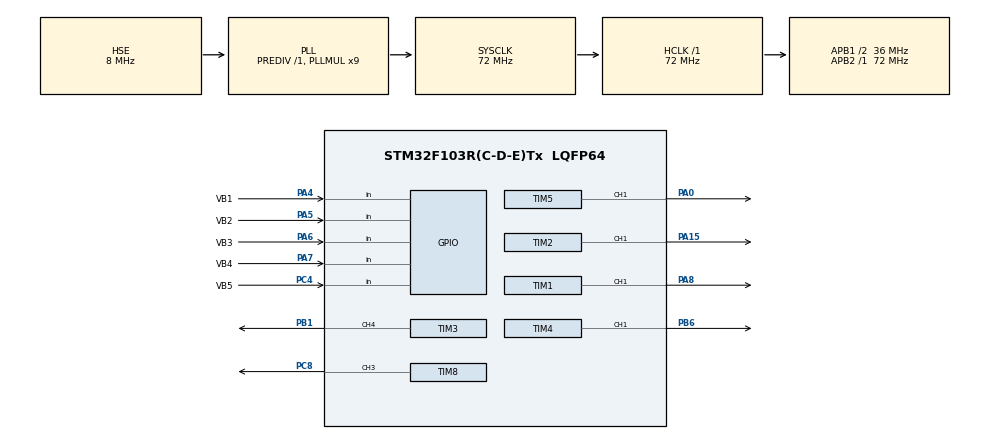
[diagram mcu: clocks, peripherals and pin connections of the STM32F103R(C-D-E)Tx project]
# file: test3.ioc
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Dma.Request0=TIM1_CH1
Dma.Request1=TIM2_CH1
Dma.Request2=TIM4_CH1
Dma.Request3=TIM3_CH4/UP
Dma.Request4=TIM5_CH1
Dma.Request5=TIM8_CH3/UP
Dma.TIM1_CH1.0.Direction=DMA_MEMORY_TO_PERIPH
Dma.TIM1_CH1.0.Instance=DMA1_Channel2
Dma.TIM1_CH1.0.MemDataAlignment=DMA_MDATAALIGN_WORD
Dma.TIM1_CH1.0.MemInc=DMA_MINC_ENABLE
Dma.TIM1_CH1.0.Mode=DMA_NORMAL
Dma.TIM1_CH1.0.PeriphDataAlignment=DMA_PDATAALIGN_WORD
Dma.TIM1_CH1.0.PeriphInc=DMA_PINC_DISABLE
Dma.TIM1_CH1.0.Priority=DMA_PRIORITY_LOW
Dma.TIM2_CH1.1.Direction=DMA_MEMORY_TO_PERIPH
Dma.TIM2_CH1.1.Instance=DMA1_Channel5
Dma.TIM2_CH1.1.MemDataAlignment=DMA_MDATAALIGN_WORD
Dma.TIM2_CH1.1.MemInc=DMA_MINC_ENABLE
Dma.TIM2_CH1.1.Mode=DMA_NORMAL
Dma.TIM2_CH1.1.PeriphDataAlignment=DMA_PDATAALIGN_WORD
Dma.TIM2_CH1.1.PeriphInc=DMA_PINC_DISABLE
Dma.TIM2_CH1.1.Priority=DMA_PRIORITY_LOW
Dma.TIM3_CH4/UP.3.Direction=DMA_MEMORY_TO_PERIPH
Dma.TIM3_CH4/UP.3.Instance=DMA1_Channel3
Dma.TIM3_CH4/UP.3.MemDataAlignment=DMA_MDATAALIGN_WORD
Dma.TIM3_CH4/UP.3.MemInc=DMA_MINC_ENABLE
Dma.TIM3_CH4/UP.3.Mode=DMA_NORMAL
Dma.TIM3_CH4/UP.3.PeriphDataAlignment=DMA_PDATAALIGN_WORD
Dma.TIM3_CH4/UP.3.PeriphInc=DMA_PINC_DISABLE
Dma.TIM3_CH4/UP.3.Priority=DMA_PRIORITY_LOW
Dma.TIM4_CH1.2.Direction=DMA_MEMORY_TO_PERIPH
Dma.TIM4_CH1.2.Instance=DMA1_Channel1
Dma.TIM4_CH1.2.MemDataAlignment=DMA_MDATAALIGN_WORD
Dma.TIM4_CH1.2.MemInc=DMA_MINC_ENABLE
Dma.TIM4_CH1.2.Mode=DMA_NORMAL
Dma.TIM4_CH1.2.PeriphDataAlignment=DMA_PDATAALIGN_WORD
Dma.TIM4_CH1.2.PeriphInc=DMA_PINC_DISABLE
Dma.TIM4_CH1.2.Priority=DMA_PRIORITY_LOW
Dma.TIM5_CH1.4.Direction=DMA_MEMORY_TO_PERIPH
Dma.TIM5_CH1.4.Instance=DMA2_Channel5
Dma.TIM5_CH1.4.MemDataAlignment=DMA_MDATAALIGN_WORD
Dma.TIM5_CH1.4.MemInc=DMA_MINC_ENABLE
Dma.TIM5_CH1.4.Mode=DMA_NORMAL
Dma.TIM5_CH1.4.PeriphDataAlignment=DMA_PDATAALIGN_WORD
Dma.TIM5_CH1.4.PeriphInc=DMA_PINC_DISABLE
Dma.TIM5_CH1.4.Priority=DMA_PRIORITY_LOW
Dma.TIM8_CH3/UP.5.Direction=DMA_MEMORY_TO_PERIPH
Dma.TIM8_CH3/UP.5.Instance=DMA2_Channel1
Dma.TIM8_CH3/UP.5.MemDataAlignment=DMA_MDATAALIGN_WORD
Dma.TIM8_CH3/UP.5.MemInc=DMA_MINC_ENABLE
Dma.TIM8_CH3/UP.5.Mode=DMA_NORMAL
Dma.TIM8_CH3/UP.5.PeriphDataAlignment=DMA_PDATAALIGN_WORD
Dma.TIM8_CH3/UP.5.PeriphInc=DMA_PINC_DISABLE
Dma.TIM8_CH3/UP.5.Priority=DMA_PRIORITY_LOW
Mcu.Family=STM32F1
Mcu.Name=STM32F103R(C-D-E)Tx
Mcu.Package=LQFP64
NVIC.DMA1_Channel1_IRQn=true\:5\:0\:true\:false\:true\:false\:true
NVIC.DMA1_Channel2_IRQn=true\:5\:0\:true\:false\:true\:false\:true
NVIC.DMA1_Channel3_IRQn=true\:5\:0\:true\:false\:true\:false\:true
NVIC.DMA1_Channel5_IRQn=true\:5\:0\:true\:false\:true\:false\:true
NVIC.DMA2_Channel1_IRQn=true\:5\:0\:true\:false\:true\:false\:true
NVIC.DMA2_Channel4_5_IRQn=true\:6\:0\:true\:false\:true\:false\:true
NVIC.PriorityGroup=NVIC_PRIORITYGROUP_4
PA0-WKUP.Signal=S_TIM5_CH1
PA13.Mode=Serial_Wire
PA13.Signal=SYS_JTMS-SWDIO
PA14.Mode=Serial_Wire
PA14.Signal=SYS_JTCK-SWCLK
PA15.Signal=S_TIM2_CH1_ETR
PA4.GPIO_Label=VB1
PA4.GPIO_PuPd=GPIO_PULLDOWN
PA4.Signal=GPIO_Input
PA5.GPIO_Label=VB2
PA5.GPIO_PuPd=GPIO_PULLDOWN
PA5.Signal=GPIO_Input
PA6.GPIO_Label=VB3
PA6.GPIO_PuPd=GPIO_PULLDOWN
PA6.Signal=GPIO_Input
PA7.GPIO_Label=VB4
PA7.GPIO_PuPd=GPIO_PULLDOWN
PA7.Signal=GPIO_Input
PA8.Signal=S_TIM1_CH1
PB1.Signal=S_TIM3_CH4
PB6.Signal=S_TIM4_CH1
PC4.GPIO_Label=VB5
PC4.GPIO_PuPd=GPIO_PULLDOWN
PC4.Signal=GPIO_Input
PC8.Signal=S_TIM8_CH3
PD0-OSC_IN.Mode=HSE-External-Oscillator
PD0-OSC_IN.Signal=RCC_OSC_IN
PD1-OSC_OUT.Mode=HSE-External-Oscillator
PD1-OSC_OUT.Signal=RCC_OSC_OUT
ProjectManager.HeapSize=0x400
ProjectManager.StackSize=0x500
ProjectManager.TargetToolchain=STM32CubeIDE
RCC.AHBFreq_Value=72000000
RCC.APB1CLKDivider=RCC_HCLK_DIV2
RCC.APB1Freq_Value=36000000
RCC.APB1TimFreq_Value=72000000
RCC.APB2Freq_Value=72000000
RCC.APB2TimFreq_Value=72000000
RCC.HCLKFreq_Value=72000000
RCC.PLLMUL=RCC_PLL_MUL9
RCC.PLLSourceVirtual=RCC_PLLSOURCE_HSE
RCC.SYSCLKFreq_VALUE=72000000
RCC.SYSCLKSource=RCC_SYSCLKSOURCE_PLLCLK
RCC.USBFreq_Value=72000000
SH.S_TIM1_CH1.0=TIM1_CH1,PWM Generation1 CH1
SH.S_TIM2_CH1_ETR.0=TIM2_CH1,PWM Generation1 CH1
SH.S_TIM3_CH4.0=TIM3_CH4,PWM Generation4 CH4
SH.S_TIM4_CH1.0=TIM4_CH1,PWM Generation1 CH1
SH.S_TIM5_CH1.0=TIM5_CH1,PWM Generation1 CH1
SH.S_TIM8_CH3.0=TIM8_CH3,PWM Generation3 CH3
TIM1.Channel-PWM\ Generation1\ CH1=TIM_CHANNEL_1
TIM1.Period=89
TIM2.Channel-PWM\ Generation1\ CH1=TIM_CHANNEL_1
TIM2.Period=89
TIM3.Channel-PWM\ Generation4\ CH4=TIM_CHANNEL_4
TIM3.Period=89
TIM4.Channel-PWM\ Generation1\ CH1=TIM_CHANNEL_1
TIM4.Period=89
TIM5.Channel-PWM\ Generation1\ CH1=TIM_CHANNEL_1
TIM5.Period=89
TIM8.Channel-PWM\ Generation3\ CH3=TIM_CHANNEL_3
TIM8.Period=89
VP_TIM1_VS_ClockSourceINT.Mode=Internal
VP_TIM2_VS_ClockSourceINT.Mode=Internal
VP_TIM3_VS_ClockSourceINT.Mode=Internal
VP_TIM4_VS_ClockSourceINT.Mode=Internal
VP_TIM5_VS_ClockSourceINT.Mode=Internal
VP_TIM8_VS_ClockSourceINT.Mode=Internal
board=custom

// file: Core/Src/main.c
/* USER CODE BEGIN Header */
/**
 ******************************************************************************
 * @file           : main.c
 * @brief          : Main program body
 ******************************************************************************
 * @attention
 *
 * Copyright (c) 2023 STMicroelectronics.
 * All rights reserved.
 *
 * This software is licensed under terms that can be found in the LICENSE file
 * in the root directory of this software component.
 * If no LICENSE file comes with this software, it is provided AS-IS.
 *
 ******************************************************************************
 */
/* USER CODE END Header */
#include "main.h"
#include "dma.h"
#include "tim.h"
#include "gpio.h"

/* USER CODE BEGIN Includes */
#include "WS2812.h"
#include "ctr.h"
// #include "Cmaster.h"
#include "vibra.h"
/* USER CODE END Includes */

void SystemClock_Config(void);

/* USER CODE BEGIN 0 */
int Step;
/* USER CODE END 0 */

int main(void)
{

  /* MCU Configuration--------------------------------------------------------*/

  /* Reset of all peripherals, Initializes the Flash interface and the Systick. */
  HAL_Init();

  /* Configure the system clock */
  SystemClock_Config();

  /* USER CODE BEGIN SysInit */
  int Step=0;
  /* USER CODE END SysInit */

  /* Initialize all configured peripherals */
  MX_GPIO_Init();
  MX_DMA_Init();
  MX_TIM1_Init();
  MX_TIM2_Init();
  MX_TIM3_Init();
  MX_TIM4_Init();
  MX_TIM5_Init();
  MX_TIM8_Init();
  /* USER CODE BEGIN 2 */
  //	ALL_UpdateBuf();
  boot_init();
  // Rand_num();
  // PC8
  /* USER CODE END 2 */

  /* Infinite loop */
  while (1) {

    /* USER CODE BEGIN 3 */
    // ʹ����
    // LED_YUAN_Init();
    //  Vibra_monitor();
    //  Trigger_Switchstate();
    //  Vibra_monitor();

    //  fan_logic();
    //  ctr_fan(Step,0x00005F);
    // Test(1,0x00005F);
    //		ALL_ClearBuf();
    //		ALL_UpdateBuf();

    //		Target_Init();

    //		ALL_ClearBuf();
    //		ALL_UpdateBuf();

    //////

    // ������
    //		Vibra_monitor();
    //		Ctr_Fan(Step,0x000010);
    //		ALL_ClearBuf();
    //		ALL_UpdateBuf();
    ///////

    //		Step = Step+2;
    //		if(Step == 34){
    //			Step = 0;
    //		}
  }
  /* USER CODE END 3 */
}

void SystemClock_Config(void)
{
  RCC_OscInitTypeDef RCC_OscInitStruct = {0};
  RCC_ClkInitTypeDef RCC_ClkInitStruct = {0};

  /** Initializes the RCC Oscillators according to the specified parameters
  * in the RCC_OscInitTypeDef structure.
  */
  RCC_OscInitStruct.OscillatorType = RCC_OSCILLATORTYPE_HSE;
  RCC_OscInitStruct.HSEState = RCC_HSE_ON;
  RCC_OscInitStruct.HSEPredivValue = RCC_HSE_PREDIV_DIV1;
  RCC_OscInitStruct.HSIState = RCC_HSI_ON;
  RCC_OscInitStruct.PLL.PLLState = RCC_PLL_ON;
  RCC_OscInitStruct.PLL.PLLSource = RCC_PLLSOURCE_HSE;
  RCC_OscInitStruct.PLL.PLLMUL = RCC_PLL_MUL9;
  if (HAL_RCC_OscConfig(&RCC_OscInitStruct) != HAL_OK)
  {
    Error_Handler();
  }
  /** Initializes the CPU, AHB and APB buses clocks
  */
  RCC_ClkInitStruct.ClockType = RCC_CLOCKTYPE_HCLK|RCC_CLOCKTYPE_SYSCLK
                              |RCC_CLOCKTYPE_PCLK1|RCC_CLOCKTYPE_PCLK2;
  RCC_ClkInitStruct.SYSCLKSource = RCC_SYSCLKSOURCE_PLLCLK;
  RCC_ClkInitStruct.AHBCLKDivider = RCC_SYSCLK_DIV1;
  RCC_ClkInitStruct.APB1CLKDivider = RCC_HCLK_DIV2;
  RCC_ClkInitStruct.APB2CLKDivider = RCC_HCLK_DIV1;

  if (HAL_RCC_ClockConfig(&RCC_ClkInitStruct, FLASH_LATENCY_2) != HAL_OK)
  {
    Error_Handler();
  }
}

/* USER CODE BEGIN 4 */

// PA3~7
// void HAL_GPIO_EXTI_Callback(uint16_t GPIO_Pin)
//{
//
////	if(GPIO_Pin == GPIO_PIN_3){
////		vibra_flag[0]=1;
////	}
////	if(GPIO_Pin == GPIO_PIN_4){
////			vibra_flag[0]=1;
////	}
////	if(GPIO_Pin == GPIO_PIN_5){
////			vibra_flag[0]=1;
////	}
////	if(GPIO_Pin == GPIO_PIN_6){
////			vibra_flag[0]=1;
////	}
////	if(GPIO_Pin == GPIO_PIN_7){
////			vibra_flag[0]=1;
////	}
//
//}

/* USER CODE END 4 */

void Error_Handler(void)
{
  __disable_irq();
  while (1) {
  }
}

#ifdef  USE_FULL_ASSERT
/**
  * @brief  Reports the name of the source file and the source line number
  *         where the assert_param error has occurred.
  * @param  file: pointer to the source file name
  * @param  line: assert_param error line source number
  * @retval None
  */
void assert_failed(uint8_t *file, uint32_t line)
{
  /* USER CODE BEGIN 6 */
  /* User can add his own implementation to report the file name and line
     number, ex: printf("Wrong parameters value: file %s on line %d\r\n", file,
     line) */
  /* USER CODE END 6 */
}
#endif /* USE_FULL_ASSERT */

/************************ (C) COPYRIGHT STMicroelectronics *****END OF FILE****/
